VERSION "created by canmatrix"

NS_ :

BS_:

BU_: SlaveOutput MasterOutput

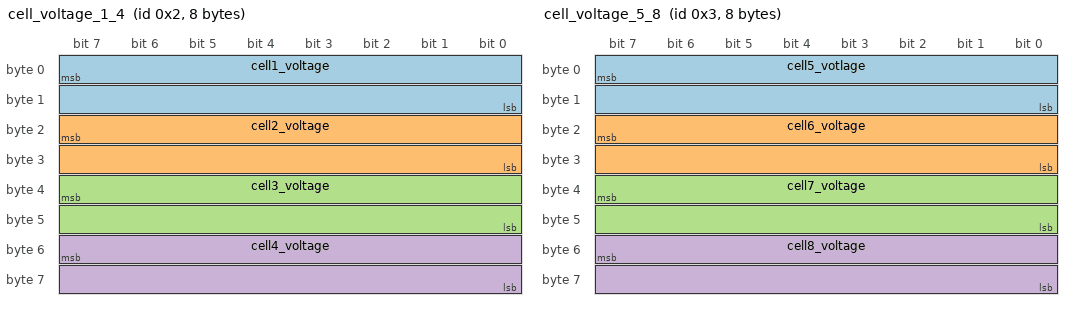
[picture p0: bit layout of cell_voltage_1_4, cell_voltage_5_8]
BO_ 2 cell_voltage_1_4: 8 SlaveOutput
 SG_ cell1_voltage : 7|16@0+ (0.0001,0) [0|5] "V" Vector__XXX
 SG_ cell2_voltage : 23|16@0+ (0.0001,0) [0|5] "V" Vector__XXX
 SG_ cell3_voltage : 39|16@0+ (0.0001,0) [0|5] "V" Vector__XXX
 SG_ cell4_voltage : 55|16@0+ (0.0001,0) [0|5] "V" Vector__XXX

BO_ 3 cell_voltage_5_8: 8 SlaveOutput
 SG_ cell5_votlage : 7|16@0+ (0.0001,0) [0|5] "V" Vector__XXX
 SG_ cell6_voltage : 23|16@0+ (0.0001,0) [0|5] "V" Vector__XXX
 SG_ cell7_voltage : 39|16@0+ (0.0001,0) [0|5] "V" Vector__XXX
 SG_ cell8_voltage : 55|16@0+ (0.0001,0) [0|5] "V" Vector__XXX

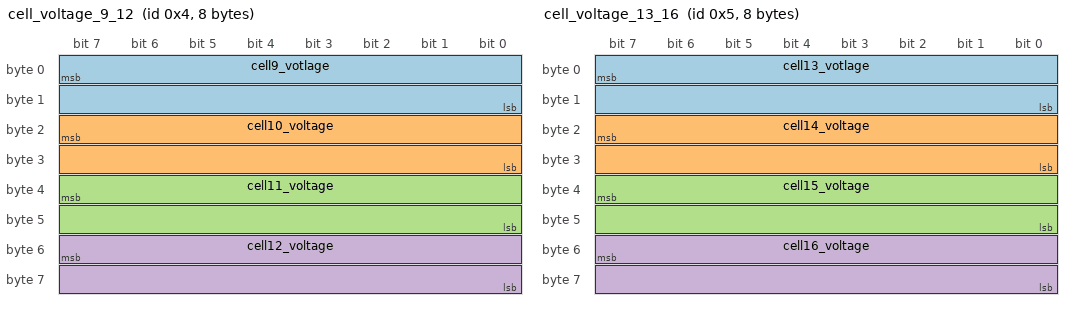
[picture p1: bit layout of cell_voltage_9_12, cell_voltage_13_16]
BO_ 4 cell_voltage_9_12: 8 SlaveOutput
 SG_ cell9_votlage : 7|16@0+ (0.0001,0) [0|5] "V" Vector__XXX
 SG_ cell10_voltage : 23|16@0+ (0.0001,0) [0|5] "V" Vector__XXX
 SG_ cell11_voltage : 39|16@0+ (0.0001,0) [0|5] "V" Vector__XXX
 SG_ cell12_voltage : 55|16@0+ (0.0001,0) [0|5] "V" Vector__XXX

BO_ 5 cell_voltage_13_16: 8 SlaveOutput
 SG_ cell13_votlage : 7|16@0+ (0.0001,0) [0|5] "V" Vector__XXX
 SG_ cell14_voltage : 23|16@0+ (0.0001,0) [0|5] "V" Vector__XXX
 SG_ cell15_voltage : 39|16@0+ (0.0001,0) [0|5] "V" Vector__XXX
 SG_ cell16_voltage : 55|16@0+ (0.0001,0) [0|5] "V" Vector__XXX

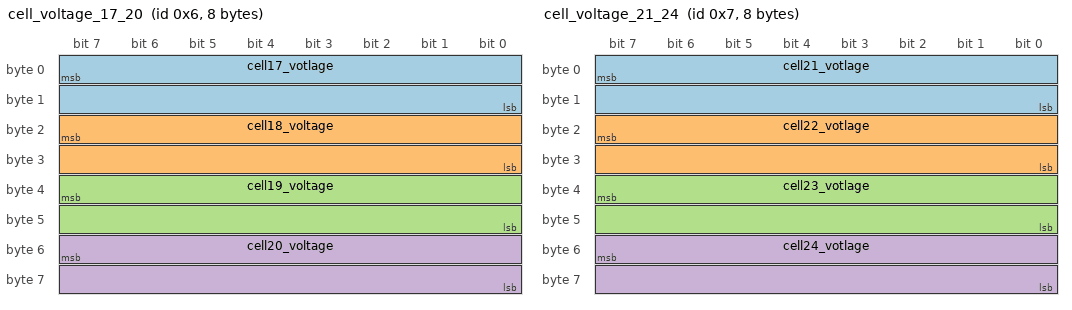
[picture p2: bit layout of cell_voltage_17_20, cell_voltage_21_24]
BO_ 6 cell_voltage_17_20: 8 SlaveOutput
 SG_ cell17_votlage : 7|16@0+ (0.0001,0) [0|5] "V" Vector__XXX
 SG_ cell18_voltage : 23|16@0+ (0.0001,0) [0|5] "V" Vector__XXX
 SG_ cell19_voltage : 39|16@0+ (0.0001,0) [0|5] "V" Vector__XXX
 SG_ cell20_voltage : 55|16@0+ (0.0001,0) [0|5] "V" Vector__XXX

BO_ 7 cell_voltage_21_24: 8 SlaveOutput
 SG_ cell21_votlage : 7|16@0+ (0.0001,0) [0|5] "V" Vector__XXX
 SG_ cell22_votlage : 23|16@0+ (0.0001,0) [0|5] "V" Vector__XXX
 SG_ cell23_votlage : 39|16@0+ (0.0001,0) [0|5] "V" Vector__XXX
 SG_ cell24_votlage : 55|16@0+ (0.0001,0) [0|5] "V" Vector__XXX

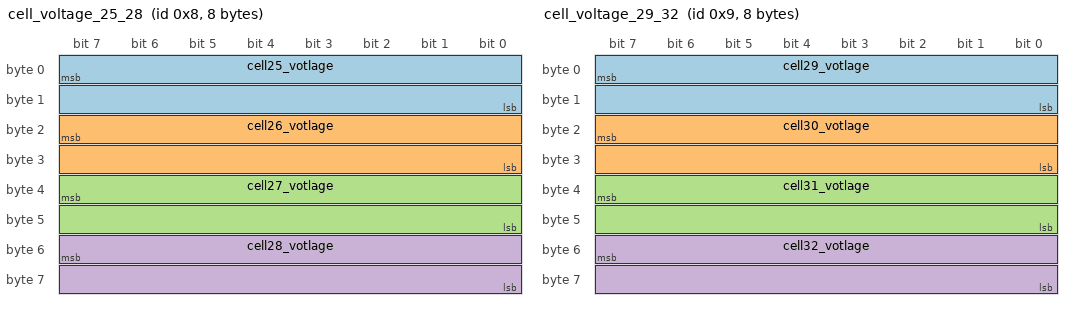
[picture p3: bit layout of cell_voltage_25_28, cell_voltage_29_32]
BO_ 8 cell_voltage_25_28: 8 SlaveOutput
 SG_ cell25_votlage : 7|16@0+ (0.0001,0) [0|5] "V" Vector__XXX
 SG_ cell26_votlage : 23|16@0+ (0.0001,0) [0|5] "V" Vector__XXX
 SG_ cell27_votlage : 39|16@0+ (0.0001,0) [0|5] "V" Vector__XXX
 SG_ cell28_votlage : 55|16@0+ (0.0001,0) [0|5] "V" Vector__XXX

BO_ 9 cell_voltage_29_32: 8 SlaveOutput
 SG_ cell29_votlage : 7|16@0+ (0.0001,0) [0|5] "V" Vector__XXX
 SG_ cell30_votlage : 23|16@0+ (0.0001,0) [0|5] "V" Vector__XXX
 SG_ cell31_votlage : 39|16@0+ (0.0001,0) [0|5] "V" Vector__XXX
 SG_ cell32_votlage : 55|16@0+ (0.0001,0) [0|5] "V" Vector__XXX

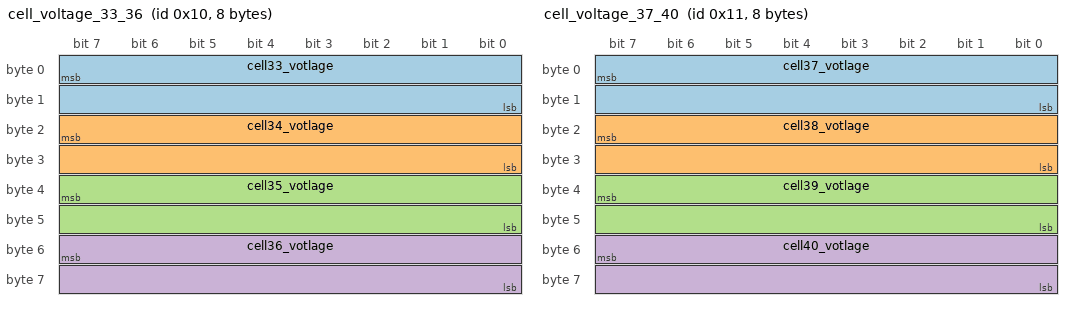
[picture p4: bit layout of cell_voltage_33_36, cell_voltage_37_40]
BO_ 16 cell_voltage_33_36: 8 SlaveOutput
 SG_ cell33_votlage : 7|16@0+ (0.0001,0) [0|5] "V" Vector__XXX
 SG_ cell34_votlage : 23|16@0+ (0.0001,0) [0|5] "V" Vector__XXX
 SG_ cell35_votlage : 39|16@0+ (0.0001,0) [0|5] "V" Vector__XXX
 SG_ cell36_votlage : 55|16@0+ (0.0001,0) [0|5] "V" Vector__XXX

BO_ 17 cell_voltage_37_40: 8 SlaveOutput
 SG_ cell37_votlage : 7|16@0+ (0.0001,0) [0|5] "V" Vector__XXX
 SG_ cell38_votlage : 23|16@0+ (0.0001,0) [0|5] "V" Vector__XXX
 SG_ cell39_votlage : 39|16@0+ (0.0001,0) [0|5] "V" Vector__XXX
 SG_ cell40_votlage : 55|16@0+ (0.0001,0) [0|5] "V" Vector__XXX

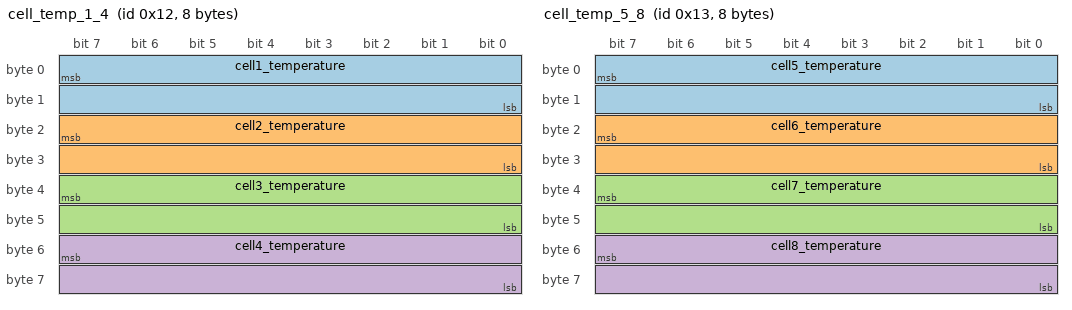
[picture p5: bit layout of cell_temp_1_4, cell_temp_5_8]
BO_ 18 cell_temp_1_4: 8 SlaveOutput
 SG_ cell1_temperature : 7|16@0+ (0.001,-20) [-20|80] "C" Vector__XXX
 SG_ cell2_temperature : 23|16@0+ (0.001,-20) [-20|80] "C" Vector__XXX
 SG_ cell3_temperature : 39|16@0+ (0.001,-20) [-20|80] "C" Vector__XXX
 SG_ cell4_temperature : 55|16@0+ (0.001,-20) [-20|80] "C" Vector__XXX

BO_ 19 cell_temp_5_8: 8 SlaveOutput
 SG_ cell5_temperature : 7|16@0+ (0.001,-20) [-20|80] "C" Vector__XXX
 SG_ cell6_temperature : 23|16@0+ (0.001,-20) [-20|80] "C" Vector__XXX
 SG_ cell7_temperature : 39|16@0+ (0.001,-20) [-20|80] "C" Vector__XXX
 SG_ cell8_temperature : 55|16@0+ (0.001,-20) [-20|80] "C" Vector__XXX

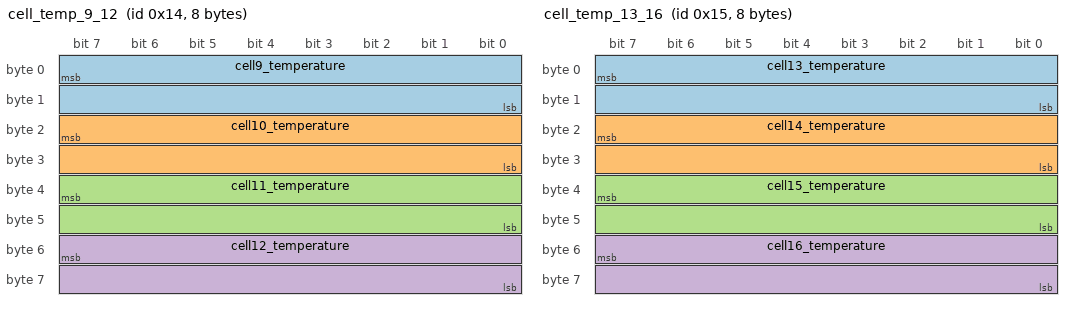
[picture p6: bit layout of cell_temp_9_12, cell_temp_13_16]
BO_ 20 cell_temp_9_12: 8 SlaveOutput
 SG_ cell9_temperature : 7|16@0+ (0.001,-20) [-20|80] "C" Vector__XXX
 SG_ cell10_temperature : 23|16@0+ (0.001,-20) [-20|80] "C" Vector__XXX
 SG_ cell11_temperature : 39|16@0+ (0.001,-20) [-20|80] "C" Vector__XXX
 SG_ cell12_temperature : 55|16@0+ (0.001,-20) [-20|80] "C" Vector__XXX

BO_ 21 cell_temp_13_16: 8 SlaveOutput
 SG_ cell13_temperature : 7|16@0+ (0.001,-20) [-20|80] "C" Vector__XXX
 SG_ cell14_temperature : 23|16@0+ (0.001,-20) [-20|80] "C" Vector__XXX
 SG_ cell15_temperature : 39|16@0+ (0.001,-20) [-20|80] "C" Vector__XXX
 SG_ cell16_temperature : 55|16@0+ (0.001,-20) [-20|80] "C" Vector__XXX

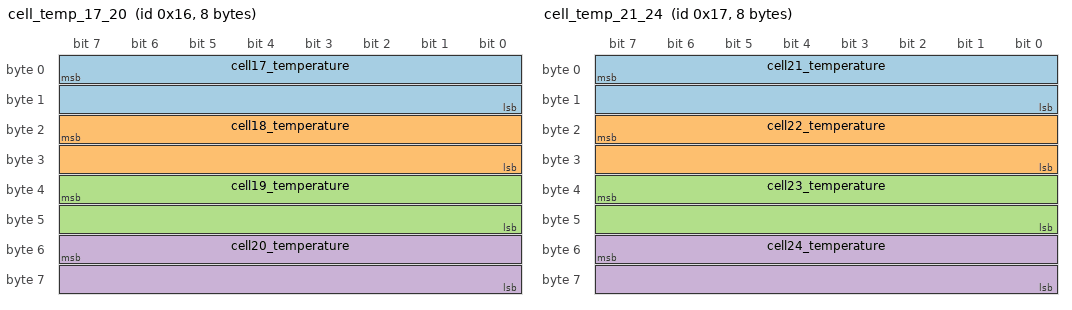
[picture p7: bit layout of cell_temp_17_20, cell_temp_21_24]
BO_ 22 cell_temp_17_20: 8 SlaveOutput
 SG_ cell17_temperature : 7|16@0+ (0.001,-20) [-20|80] "C" Vector__XXX
 SG_ cell18_temperature : 23|16@0+ (0.001,-20) [-20|80] "C" Vector__XXX
 SG_ cell19_temperature : 39|16@0+ (0.001,-20) [-20|80] "C" Vector__XXX
 SG_ cell20_temperature : 55|16@0+ (0.001,-20) [-20|80] "C" Vector__XXX

BO_ 23 cell_temp_21_24: 8 SlaveOutput
 SG_ cell21_temperature : 7|16@0+ (0.001,-20) [-20|80] "C" Vector__XXX
 SG_ cell22_temperature : 23|16@0+ (0.001,-20) [-20|80] "C" Vector__XXX
 SG_ cell23_temperature : 39|16@0+ (0.001,-20) [-20|80] "C" Vector__XXX
 SG_ cell24_temperature : 55|16@0+ (0.001,-20) [-20|80] "C" Vector__XXX

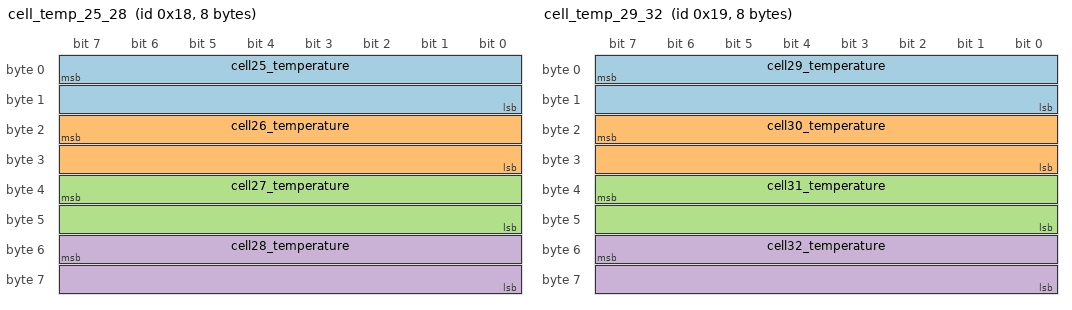
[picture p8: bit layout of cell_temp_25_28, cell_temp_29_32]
BO_ 24 cell_temp_25_28: 8 SlaveOutput
 SG_ cell25_temperature : 7|16@0+ (0.001,-20) [-20|80] "C" Vector__XXX
 SG_ cell26_temperature : 23|16@0+ (0.001,-20) [-20|80] "C" Vector__XXX
 SG_ cell27_temperature : 39|16@0+ (0.001,-20) [-20|80] "C" Vector__XXX
 SG_ cell28_temperature : 55|16@0+ (0.001,-20) [-20|80] "C" Vector__XXX

BO_ 25 cell_temp_29_32: 8 SlaveOutput
 SG_ cell29_temperature : 7|16@0+ (0.001,-20) [-20|80] "C" Vector__XXX
 SG_ cell30_temperature : 23|16@0+ (0.001,-20) [-20|80] "C" Vector__XXX
 SG_ cell31_temperature : 39|16@0+ (0.001,-20) [-20|80] "C" Vector__XXX
 SG_ cell32_temperature : 55|16@0+ (0.001,-20) [-20|80] "C" Vector__XXX

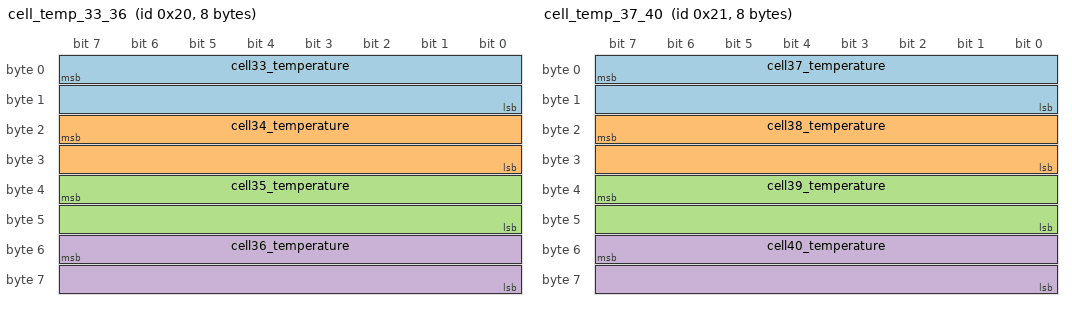
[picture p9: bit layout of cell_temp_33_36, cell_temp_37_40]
BO_ 32 cell_temp_33_36: 8 SlaveOutput
 SG_ cell33_temperature : 7|16@0+ (0.001,-20) [-20|80] "C" Vector__XXX
 SG_ cell34_temperature : 23|16@0+ (0.001,-20) [-20|80] "C" Vector__XXX
 SG_ cell35_temperature : 39|16@0+ (0.001,-20) [-20|80] "C" Vector__XXX
 SG_ cell36_temperature : 55|16@0+ (0.001,-20) [-20|80] "C" Vector__XXX

BO_ 33 cell_temp_37_40: 8 SlaveOutput
 SG_ cell37_temperature : 7|16@0+ (0.001,-20) [-20|80] "C" Vector__XXX
 SG_ cell38_temperature : 23|16@0+ (0.001,-20) [-20|80] "C" Vector__XXX
 SG_ cell39_temperature : 39|16@0+ (0.001,-20) [-20|80] "C" Vector__XXX
 SG_ cell40_temperature : 55|16@0+ (0.001,-20) [-20|80] "C" Vector__XXX

BO_ 34 cell_bal_cmd: 8 SlaveOutput
 SG_ cell1_cb_cmd : 7|1@0+ (1,0) [0|1] "state" Vector__XXX
 SG_ cell2_cb_cmd : 6|1@0+ (1,0) [0|1] "state" Vector__XXX
 SG_ cell3_cb_cmd : 5|1@0+ (1,0) [0|1] "state" Vector__XXX
 SG_ cell4_cb_cmd : 4|1@0+ (1,0) [0|1] "state" Vector__XXX
 SG_ cell5_cb_cmd : 3|1@0+ (1,0) [0|1] "state" Vector__XXX
 SG_ cell6_cb_cmd : 2|1@0+ (1,0) [0|1] "state" Vector__XXX
 SG_ cell7_cb_cmd : 1|1@0+ (1,0) [0|1] "state" Vector__XXX
 SG_ cell8_cb_cmd : 0|1@0+ (1,0) [0|1] "state" Vector__XXX
 SG_ cell9_cb_cmd : 15|1@0+ (1,0) [0|1] "state" Vector__XXX
 SG_ cell10_cb_cmd : 14|1@0+ (1,0) [0|1] "state" Vector__XXX
 SG_ cell11_cb_cmd : 13|1@0+ (1,0) [0|1] "state" Vector__XXX
 SG_ cell12_cb_cmd : 12|1@0+ (1,0) [0|1] "state" Vector__XXX
 SG_ cell13_cb_cmd : 11|1@0+ (1,0) [0|1] "state" Vector__XXX
 SG_ cell14_cb_cmd : 10|1@0+ (1,0) [0|1] "state" Vector__XXX
 SG_ cell15_cb_cmd : 9|1@0+ (1,0) [0|1] "state" Vector__XXX
 SG_ cell16_cb_cmd : 8|1@0+ (1,0) [0|1] "state" Vector__XXX
 SG_ cell17_cb_cmd : 23|1@0+ (1,0) [0|1] "state" Vector__XXX
 SG_ cell18_cb_cmd : 22|1@0+ (1,0) [0|1] "state" Vector__XXX
 SG_ cell19_cb_cmd : 21|1@0+ (1,0) [0|1] "state" Vector__XXX
 SG_ cell20_cb_cmd : 20|1@0+ (1,0) [0|1] "state" Vector__XXX
 SG_ cell21_cb_cmd : 19|1@0+ (1,0) [0|1] "state" Vector__XXX
 SG_ cell22_cb_cmd : 18|1@0+ (1,0) [0|1] "state" Vector__XXX
 SG_ cell23_cb_cmd : 17|1@0+ (1,0) [0|1] "state" Vector__XXX
 SG_ cell24_cb_cmd : 16|1@0+ (1,0) [0|1] "state" Vector__XXX
 SG_ cell25_cb_cmd : 31|1@0+ (1,0) [0|1] "state" Vector__XXX
 SG_ cell26_cb_cmd : 30|1@0+ (1,0) [0|1] "state" Vector__XXX
 SG_ cell27_cb_cmd : 29|1@0+ (1,0) [0|1] "state" Vector__XXX
 SG_ cell28_cb_cmd : 28|1@0+ (1,0) [0|1] "state" Vector__XXX
 SG_ cell29_cb_cmd : 27|1@0+ (1,0) [0|1] "state" Vector__XXX
 SG_ cell30_cb_cmd : 26|1@0+ (1,0) [0|1] "state" Vector__XXX
 SG_ cell31_cb_cmd : 25|1@0+ (1,0) [0|1] "state" Vector__XXX
 SG_ cell32_cb_cmd : 24|1@0+ (1,0) [0|1] "state" Vector__XXX
 SG_ cell33_cb_cmd : 39|1@0+ (1,0) [0|1] "state" Vector__XXX
 SG_ cell34_cb_cmd : 38|1@0+ (1,0) [0|1] "state" Vector__XXX
 SG_ cell35_cb_cmd : 37|1@0+ (1,0) [0|1] "state" Vector__XXX
 SG_ cell36_cb_cmd : 36|1@0+ (1,0) [0|1] "state" Vector__XXX
 SG_ cell37_cb_cmd : 35|1@0+ (1,0) [0|1] "state" Vector__XXX
 SG_ cell38_cb_cmd : 34|1@0+ (1,0) [0|1] "state" Vector__XXX
 SG_ cell39_cb_cmd : 33|1@0+ (1,0) [0|1] "state" Vector__XXX
 SG_ cell40_cb_cmd : 32|1@0+ (1,0) [0|1] "state" Vector__XXX

BO_ 35 socket_charging: 8 MasterOutput
 SG_ charger_signal : 7|1@0+ (1,0) [0|1] "state" Vector__XXX

BO_ 36 pack_data: 8 SlaveOutput
 SG_ pack_current : 7|24@0- (0.001,0) [-200|200] "A" Vector__XXX
 SG_ pack_voltage : 31|24@0+ (0.001,0) [0|200] "V" Vector__XXX

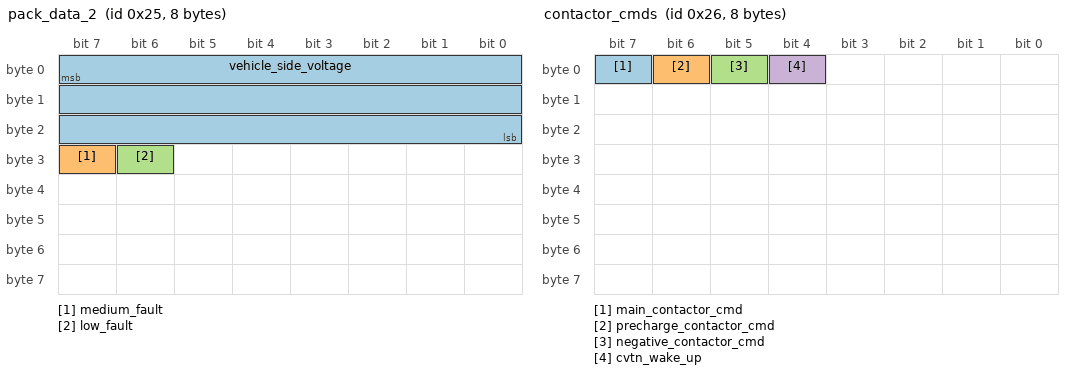
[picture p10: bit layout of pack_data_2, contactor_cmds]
BO_ 37 pack_data_2: 8 SlaveOutput
 SG_ vehicle_side_voltage : 7|24@0+ (1,0) [0|200] "0.001V" Vector__XXX
 SG_ medium_fault : 31|1@0+ (1,0) [0|1] "state" Vector__XXX
 SG_ low_fault : 30|1@0+ (1,0) [0|1] "state" Vector__XXX

BO_ 38 contactor_cmds: 8 MasterOutput
 SG_ main_contactor_cmd : 7|1@0+ (1,0) [0|1] "state" Vector__XXX
 SG_ precharge_contactor_cmd : 6|1@0+ (1,0) [0|1] "state" Vector__XXX
 SG_ negative_contactor_cmd : 5|1@0+ (1,0) [0|1] "state" Vector__XXX
 SG_ cvtn_wake_up : 4|1@0+ (1,0) [0|1] "state" Vector__XXX

BO_ 39 fan_cmd: 8 MasterOutput
 SG_ fan_cmd_pct : 7|10@0+ (0.1,0) [0|100] "pct" Vector__XXX
